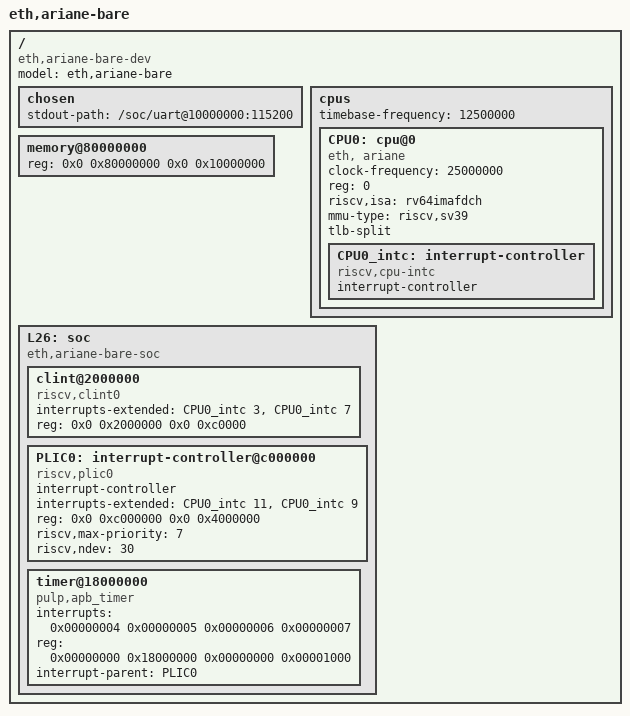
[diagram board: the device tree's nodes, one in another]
/dts-v1/;

#include <dt-bindings/gpio/gpio.h>

/ {
  #address-cells = <2>;
  #size-cells = <2>;
  compatible = "eth,ariane-bare-dev";
  model = "eth,ariane-bare";
  chosen {
    stdout-path = "/soc/uart@10000000:115200";
    //tick-timer =  "/cpus/cpu@0";
  };
  cpus {
    #address-cells = <1>;
    #size-cells = <0>;
    timebase-frequency = <12500000>; // 12.5 MHz
    CPU0: cpu@0 {
      clock-frequency = <25000000>; // 25 MHz
      device_type = "cpu";
      reg = <0>;
      status = "okay";
      compatible = "eth, ariane", "riscv";
      riscv,isa = "rv64imafdch";
      mmu-type = "riscv,sv39";
      tlb-split;
      // HLIC - hart local interrupt controller
      CPU0_intc: interrupt-controller {
        #interrupt-cells = <1>;
        interrupt-controller;
        compatible = "riscv,cpu-intc";
      };
    };
  };
  memory@80000000 {
    device_type = "memory";
    reg = <0x0 0x80000000 0x0 0x10000000>;
  };
  L26: soc {
    #address-cells = <2>;
    #size-cells = <2>;
    compatible = "eth,ariane-bare-soc", "simple-bus";
    ranges;
    clint@2000000 {
      compatible = "riscv,clint0";
      interrupts-extended = <&CPU0_intc 3 &CPU0_intc 7>;
      reg = <0x0 0x2000000 0x0 0xc0000>;
      reg-names = "control";
    };
    PLIC0: interrupt-controller@c000000 {
      #address-cells = <0>;
      #interrupt-cells = <1>;
      compatible = "riscv,plic0";
      interrupt-controller;
      interrupts-extended = <&CPU0_intc 11 &CPU0_intc 9>;
      reg = <0x0 0xc000000 0x0 0x4000000>;
      riscv,max-priority = <7>;
      riscv,ndev = <30>;
    };
    timer@18000000 {
      compatible = "pulp,apb_timer";
      interrupts = <0x00000004 0x00000005 0x00000006 0x00000007>;
      reg = <0x00000000 0x18000000 0x00000000 0x00001000>;
      interrupt-parent = <&PLIC0>;
      reg-names = "control";
    };
  };
};
